AUTOSAR XML (schema 00048)
package /AdaptiveApplicationSwComponentTypes
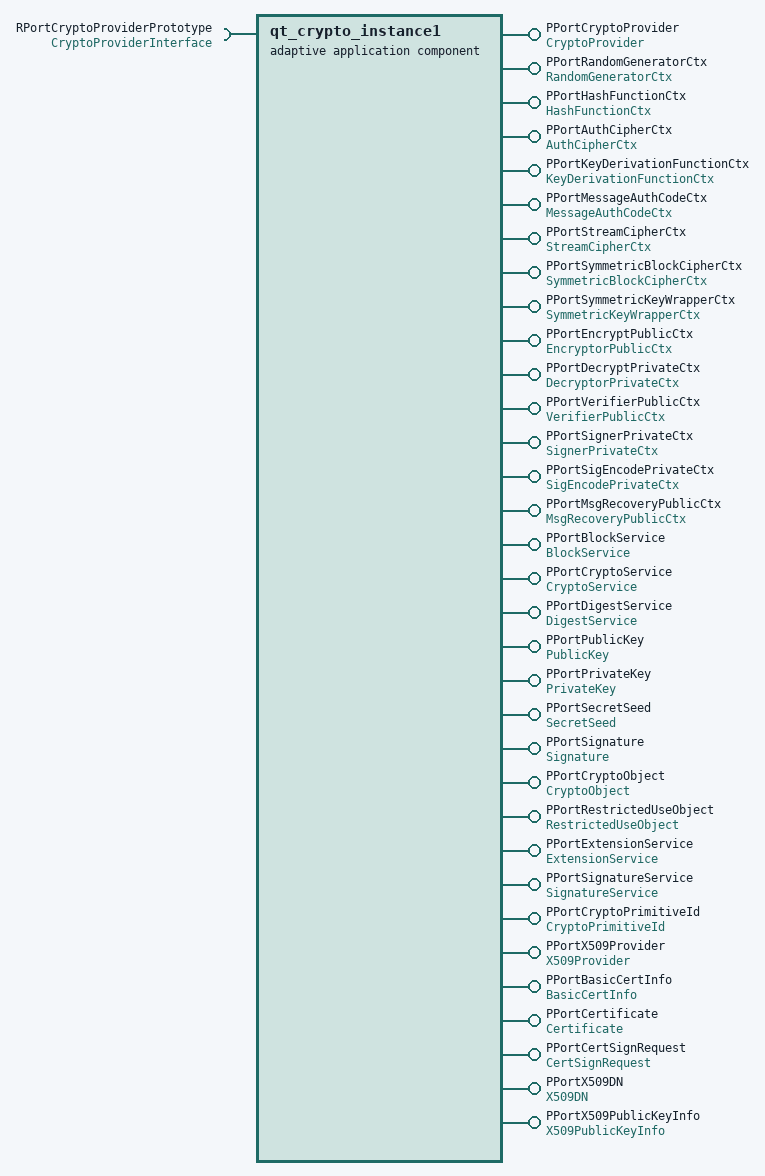
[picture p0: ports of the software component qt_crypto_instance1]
  adaptive application sw component type qt_crypto_instance1: category=APPLICATION_LEVEL
    9 x provide port:
      PPortCryptoProvider: provided-interface=CryptoProvider
      PPortRandomGeneratorCtx: provided-interface=RandomGeneratorCtx
      PPortHashFunctionCtx: provided-interface=HashFunctionCtx
      PPortAuthCipherCtx: provided-interface=AuthCipherCtx
      PPortKeyDerivationFunctionCtx: provided-interface=KeyDerivationFunctionCtx
      PPortMessageAuthCodeCtx: provided-interface=MessageAuthCodeCtx
      PPortStreamCipherCtx: provided-interface=StreamCipherCtx
      PPortSymmetricBlockCipherCtx: provided-interface=SymmetricBlockCipherCtx
      PPortSymmetricKeyWrapperCtx: provided-interface=SymmetricKeyWrapperCtx
    require port RPortCryptoProviderPrototype: required-interface=CryptoProviderInterface
    24 x provide port:
      PPortEncryptPublicCtx: provided-interface=EncryptorPublicCtx
      PPortDecryptPrivateCtx: provided-interface=DecryptorPrivateCtx
      PPortVerifierPublicCtx: provided-interface=VerifierPublicCtx
      PPortSignerPrivateCtx: provided-interface=SignerPrivateCtx
      PPortSigEncodePrivateCtx: provided-interface=SigEncodePrivateCtx
      PPortMsgRecoveryPublicCtx: provided-interface=MsgRecoveryPublicCtx
      PPortBlockService: provided-interface=BlockService
      PPortCryptoService: provided-interface=CryptoService
      PPortDigestService: provided-interface=DigestService
      PPortPublicKey: provided-interface=PublicKey
      PPortPrivateKey: provided-interface=PrivateKey
      PPortSecretSeed: provided-interface=SecretSeed
      PPortSignature: provided-interface=Signature
      PPortCryptoObject: provided-interface=CryptoObject
      PPortRestrictedUseObject: provided-interface=RestrictedUseObject
      PPortExtensionService: provided-interface=ExtensionService
      PPortSignatureService: provided-interface=SignatureService
      PPortCryptoPrimitiveId: provided-interface=CryptoPrimitiveId
      PPortX509Provider: provided-interface=X509Provider
      PPortBasicCertInfo: provided-interface=BasicCertInfo
      PPortCertificate: provided-interface=Certificate
      PPortCertSignRequest: provided-interface=CertSignRequest
      PPortX509DN: provided-interface=X509DN
      PPortX509PublicKeyInfo: provided-interface=X509PublicKeyInfo
